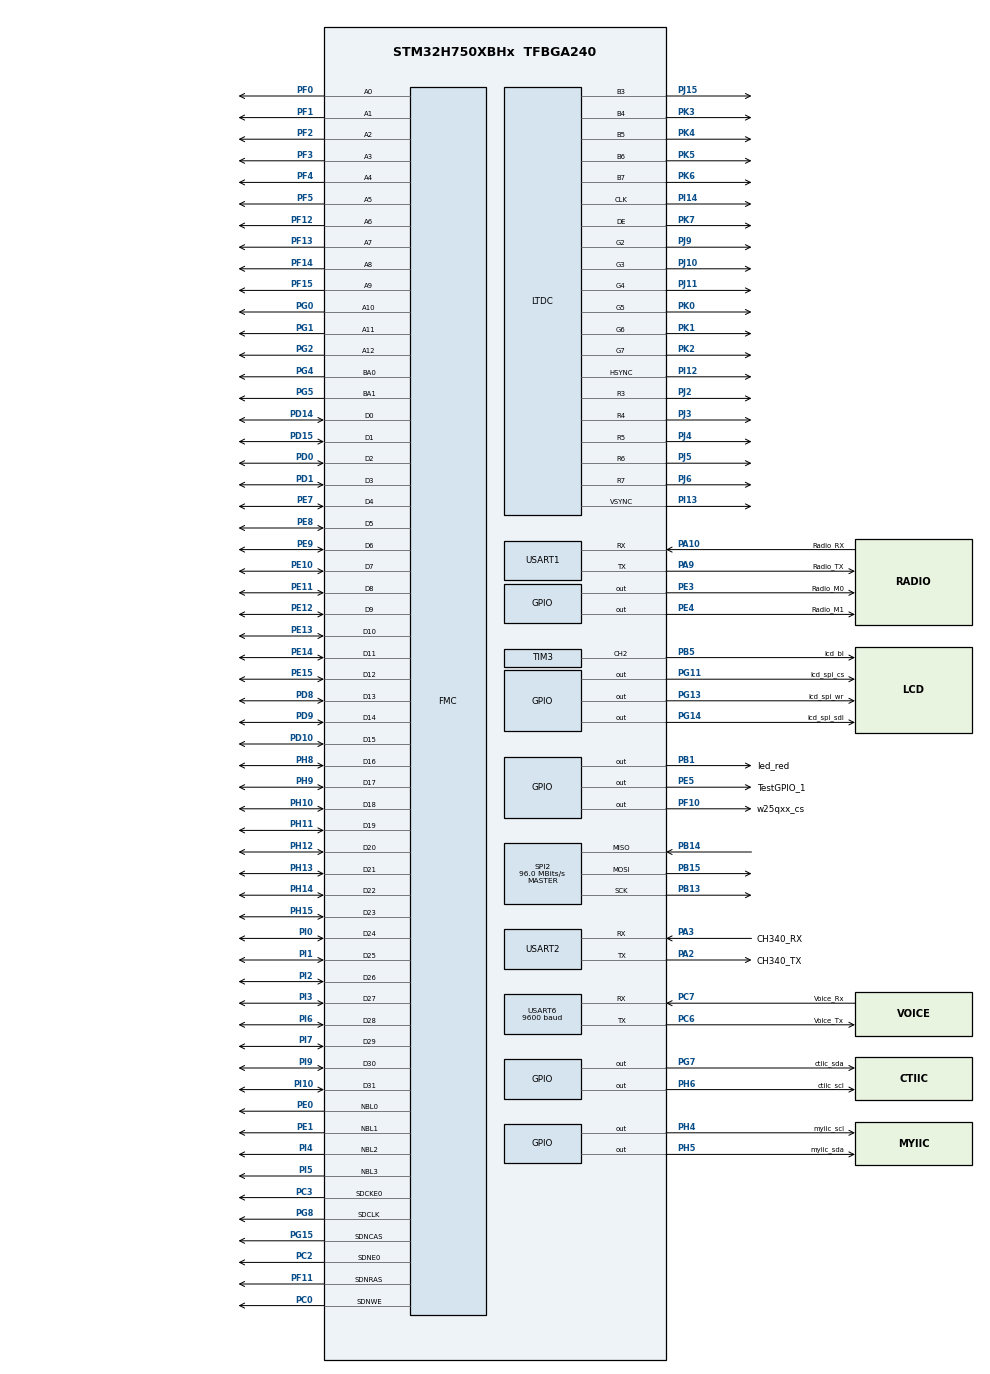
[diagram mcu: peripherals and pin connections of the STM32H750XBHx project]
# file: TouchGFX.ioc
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ADC3.Channel-0\#ChannelRegularConversion=ADC_CHANNEL_TEMPSENSOR
ADC3.ClockPrescalerADC3=ADC_CLOCK_ASYNC_DIV256
ADC3.NbrOfConversionFlag=1
ADC3.OffsetNumber-0\#ChannelRegularConversion=ADC_OFFSET_NONE
ADC3.OffsetSignedSaturation-0\#ChannelRegularConversion=DISABLE
ADC3.Rank-0\#ChannelRegularConversion=1
ADC3.SamplingTime-0\#ChannelRegularConversion=ADC_SAMPLETIME_810CYCLES_5
CORTEX_M7.CPU_DCache=Enabled
CORTEX_M7.CPU_ICache=Enabled
CORTEX_M7.DisableExec_Spec=MPU_INSTRUCTION_ACCESS_ENABLE
CORTEX_M7.Enable_S-Cortex_Memory_Protection_Unit_Region1_Settings_S=__NULL
CORTEX_M7.IsBufferable_Spec=MPU_ACCESS_BUFFERABLE
CORTEX_M7.IsCacheable_Spec=MPU_ACCESS_CACHEABLE
CORTEX_M7.TypeExtField_Spec=MPU_TEX_LEVEL0
CORTEX_M7.default_mode_Activation=1
DMA2D.ColorMode=DMA2D_OUTPUT_RGB565
Dma.Request0=USART1_TX
Dma.USART1_TX.0.Direction=DMA_MEMORY_TO_PERIPH
Dma.USART1_TX.0.EventEnable=DISABLE
Dma.USART1_TX.0.FIFOMode=DMA_FIFOMODE_DISABLE
Dma.USART1_TX.0.Instance=DMA1_Stream0
Dma.USART1_TX.0.MemDataAlignment=DMA_MDATAALIGN_BYTE
Dma.USART1_TX.0.MemInc=DMA_MINC_ENABLE
Dma.USART1_TX.0.Mode=DMA_NORMAL
Dma.USART1_TX.0.PeriphDataAlignment=DMA_PDATAALIGN_BYTE
Dma.USART1_TX.0.PeriphInc=DMA_PINC_DISABLE
Dma.USART1_TX.0.Polarity=HAL_DMAMUX_REQ_GEN_RISING
Dma.USART1_TX.0.Priority=DMA_PRIORITY_LOW
Dma.USART1_TX.0.RequestNumber=1
Dma.USART1_TX.0.SignalID=NONE
Dma.USART1_TX.0.SyncEnable=DISABLE
Dma.USART1_TX.0.SyncPolarity=HAL_DMAMUX_SYNC_NO_EVENT
Dma.USART1_TX.0.SyncRequestNumber=1
Dma.USART1_TX.0.SyncSignalID=NONE
FMC.CASLatency2=FMC_SDRAM_CAS_LATENCY_2
FMC.ColumnBitsNumber2=FMC_SDRAM_COLUMN_BITS_NUM_9
FMC.ExitSelfRefreshDelay2=8
FMC.LoadToActiveDelay2=2
FMC.RCDDelay2=2
FMC.RPDelay1=2
FMC.RPDelay2=2
FMC.ReadBurst1=FMC_SDRAM_RBURST_ENABLE
FMC.ReadBurst2=FMC_SDRAM_RBURST_ENABLE
FMC.RowCycleDelay1=6
FMC.RowCycleDelay2=6
FMC.SDClockPeriod1=FMC_SDRAM_CLOCK_PERIOD_2
FMC.SDClockPeriod2=FMC_SDRAM_CLOCK_PERIOD_2
FMC.SelfRefreshTime2=6
FMC.WriteRecoveryTime2=4
FREERTOS.BinarySemaphores01=RadioUART_BinSem,Dynamic,NULL;RenCPUTempBinSem,Dynamic,NULL;UpRadioDatBinSem,Dynamic,NULL
FREERTOS.INCLUDE_vTaskDelayUntil=1
FREERTOS.Queues01=USB_StateQueue,16,uint8_t,0,Dynamic,NULL,NULL;GUI_ControlTaskQueue,16,uint8_t,0,Dynamic,NULL,NULL;Task_ControlGUIQueue,16,uint8_t,0,Dynamic,NULL,NULL
FREERTOS.Tasks01=touchGFX,2,4096,TouchGFX_Task,As weak,NULL,Dynamic,NULL,NULL;GUI_MesProcess,3,1024,GUI_MesProcess_Task,Default,NULL,Dynamic,NULL,NULL;SendContGUIMess,0,256,SendContGUIMess_Task,Default,NULL,Dynamic,NULL,NULL;IwdgTask,-3,128,StartIwdgTask,Default,NULL,Dynamic,NULL,NULL;PerDataProcess_,1,256,PerDataProcess_Task,Default,NULL,Dynamic,NULL,NULL
FREERTOS.configGENERATE_RUN_TIME_STATS=1
FREERTOS.configTOTAL_HEAP_SIZE=30720
FREERTOS.configUSE_APPLICATION_TASK_TAG=1
FREERTOS.configUSE_COUNTING_SEMAPHORES=1
FREERTOS.configUSE_IDLE_HOOK=1
FREERTOS.configUSE_RECURSIVE_MUTEXES=1
FREERTOS.configUSE_STATS_FORMATTING_FUNCTIONS=1
FREERTOS.configUSE_TICK_HOOK=1
FREERTOS.configUSE_TIMERS=0
FREERTOS.configUSE_TRACE_FACILITY=1
IWDG1.Prescaler=IWDG_PRESCALER_32
IWDG1.Reload=1000
IWDG1.Window=1000
LTDC.ActiveH=800
LTDC.ActiveW=480
LTDC.Alpha_L0=255
LTDC.Alpha_L1=255
LTDC.Blue_L1=255
LTDC.FBStartAdress_L0=0xC0000000
LTDC.Green_L0=0
LTDC.HBP=0x58
LTDC.HFP=0x30
LTDC.HSPolarity=LTDC_HSPOLARITY_AL
LTDC.HSync=0x60
LTDC.ImageHeight_L0=800
LTDC.ImageHeight_L1=800
LTDC.ImageWidth_L0=480
LTDC.Layers=0
LTDC.PCPolarity=LTDC_PCPOLARITY_IPC
LTDC.PixelFormat_L0=LTDC_PIXEL_FORMAT_RGB565
LTDC.VBP=0x03
LTDC.VFP=0x02
LTDC.VSPolarity=LTDC_VSPOLARITY_AL
LTDC.VSync=0x0f
LTDC.WindowX1_L0=480
LTDC.WindowX1_L1=480
LTDC.WindowY1_L0=800
LTDC.WindowY1_L1=800
Mcu.Family=STM32H7
Mcu.Name=STM32H750XBHx
Mcu.Package=TFBGA240
NVIC.DMA1_Stream0_IRQn=true\:5\:0\:false\:false\:true\:true\:false\:true\:true
NVIC.DMA2D_IRQn=true\:9\:0\:true\:false\:true\:true\:true\:true\:true
NVIC.LTDC_IRQn=true\:9\:0\:true\:false\:true\:true\:true\:true\:true
NVIC.PriorityGroup=NVIC_PRIORITYGROUP_4
NVIC.RCC_IRQn=true\:5\:0\:false\:false\:true\:true\:true\:false\:true
NVIC.RTC_Alarm_IRQn=true\:14\:0\:true\:false\:true\:true\:true\:true\:true
NVIC.TIM15_IRQn=true\:6\:0\:true\:false\:true\:true\:true\:true\:true
NVIC.TIM16_IRQn=true\:5\:0\:false\:false\:true\:true\:true\:true\:true
NVIC.TIM6_DAC_IRQn=true\:6\:0\:true\:false\:true\:true\:true\:true\:true
NVIC.TIM7_IRQn=true\:15\:0\:true\:false\:true\:false\:false\:true\:true
NVIC.TIM8_BRK_TIM12_IRQn=true\:7\:0\:true\:false\:true\:true\:true\:true\:true
NVIC.TimeBase=TIM7_IRQn
NVIC.TimeBaseIP=TIM7
NVIC.USART1_IRQn=true\:7\:0\:true\:false\:true\:true\:true\:true\:true
NVIC.USART2_IRQn=true\:6\:0\:true\:false\:true\:true\:true\:true\:true
NVIC.USART6_IRQn=true\:8\:0\:true\:false\:true\:true\:true\:true\:true
PA10.GPIO_Label=Radio_RX
PA10.GPIO_Speed=GPIO_SPEED_FREQ_VERY_HIGH
PA10.Mode=Asynchronous
PA10.Signal=USART1_RX
PA13\ (JTMS/SWDIO).Mode=Serial_Wire
PA13\ (JTMS/SWDIO).Signal=DEBUG_JTMS-SWDIO
PA14\ (JTCK/SWCLK).Mode=Serial_Wire
PA14\ (JTCK/SWCLK).Signal=DEBUG_JTCK-SWCLK
PA2.GPIO_Label=CH340_TX
PA2.GPIO_Speed=GPIO_SPEED_FREQ_VERY_HIGH
PA2.Mode=Asynchronous
PA2.Signal=USART2_TX
PA3.GPIO_Label=CH340_RX
PA3.GPIO_Speed=GPIO_SPEED_FREQ_VERY_HIGH
PA3.Mode=Asynchronous
PA3.Signal=USART2_RX
PA9.GPIO_Label=Radio_TX
PA9.GPIO_Speed=GPIO_SPEED_FREQ_VERY_HIGH
PA9.Mode=Asynchronous
PA9.Signal=USART1_TX
PB1.GPIO_Label=led_red
PB1.GPIO_PuPd=GPIO_PULLUP
PB1.GPIO_Speed=GPIO_SPEED_FREQ_VERY_HIGH
PB1.PinState=GPIO_PIN_SET
PB1.Signal=GPIO_Output
PB13.GPIO_PuPd=GPIO_PULLUP
PB13.GPIO_Speed=GPIO_SPEED_FREQ_VERY_HIGH
PB13.Mode=Full_Duplex_Master
PB13.PinAttribute=Free
PB13.Signal=SPI2_SCK
PB14.GPIO_PuPd=GPIO_PULLUP
PB14.GPIO_Speed=GPIO_SPEED_FREQ_VERY_HIGH
PB14.Mode=Full_Duplex_Master
PB14.PinAttribute=Free
PB14.Signal=SPI2_MISO
PB15.GPIO_PuPd=GPIO_PULLUP
PB15.GPIO_Speed=GPIO_SPEED_FREQ_VERY_HIGH
PB15.Mode=Full_Duplex_Master
PB15.Signal=SPI2_MOSI
PB5.GPIO_Label=lcd_bl
PB5.GPIO_PuPd=GPIO_PULLUP
PB5.GPIO_Speed=GPIO_SPEED_FREQ_VERY_HIGH
PB5.Signal=S_TIM3_CH2
PC0.PinAttribute=Free
PC0.Signal=FMC_SDNWE
PC2.Mode=SdramChipSelect1_2
PC2.PinAttribute=Free
PC2.Signal=FMC_SDNE0
PC3.Mode=SdramChipSelect1_2
PC3.PinAttribute=Free
PC3.Signal=FMC_SDCKE0
PC6.GPIO_Label=Voice_Tx
PC6.GPIO_Speed=GPIO_SPEED_FREQ_VERY_HIGH
PC6.Mode=Asynchronous
PC6.Signal=USART6_TX
PC7.GPIO_Label=Voice_Rx
PC7.GPIO_Speed=GPIO_SPEED_FREQ_VERY_HIGH
PC7.Mode=Asynchronous
PC7.Signal=USART6_RX
PD0.Signal=FMC_D2_DA2
PD1.Signal=FMC_D3_DA3
PD10.Signal=FMC_D15_DA15
PD14.Signal=FMC_D0_DA0
PD15.Signal=FMC_D1_DA1
PD8.PinAttribute=Free
PD8.Signal=FMC_D13_DA13
PD9.Signal=FMC_D14_DA14
PE0.Signal=FMC_NBL0
PE1.PinAttribute=Free
PE1.Signal=FMC_NBL1
PE10.Signal=FMC_D7_DA7
PE11.Signal=FMC_D8_DA8
PE12.Signal=FMC_D9_DA9
PE13.Signal=FMC_D10_DA10
PE14.PinAttribute=Free
PE14.Signal=FMC_D11_DA11
PE15.Signal=FMC_D12_DA12
PE3.GPIO_Label=Radio_M0
PE3.GPIO_Speed=GPIO_SPEED_FREQ_VERY_HIGH
PE3.Signal=GPIO_Output
PE4.GPIO_Label=Radio_M1
PE4.GPIO_PuPd=GPIO_NOPULL
PE4.GPIO_Speed=GPIO_SPEED_FREQ_VERY_HIGH
PE4.Signal=GPIO_Output
PE5.GPIO_Label=TestGPIO_1
PE5.GPIO_PuPd=GPIO_PULLDOWN
PE5.GPIO_Speed=GPIO_SPEED_FREQ_VERY_HIGH
PE5.Signal=GPIO_Output
PE7.PinAttribute=Free
PE7.Signal=FMC_D4_DA4
PE8.Signal=FMC_D5_DA5
PE9.Signal=FMC_D6_DA6
PF0.Signal=FMC_A0
PF1.Signal=FMC_A1
PF10.GPIO_Label=w25qxx_cs
PF10.GPIO_PuPd=GPIO_PULLUP
PF10.GPIO_Speed=GPIO_SPEED_FREQ_VERY_HIGH
PF10.PinState=GPIO_PIN_SET
PF10.Signal=GPIO_Output
PF11.Signal=FMC_SDNRAS
PF12.Signal=FMC_A6
PF13.Signal=FMC_A7
PF14.Signal=FMC_A8
PF15.Signal=FMC_A9
PF2.Signal=FMC_A2
PF3.PinAttribute=Free
PF3.Signal=FMC_A3
PF4.PinAttribute=Free
PF4.Signal=FMC_A4
PF5.PinAttribute=Free
PF5.Signal=FMC_A5
PG0.Signal=FMC_A10
PG1.PinAttribute=Free
PG1.Signal=FMC_A11
PG11.GPIO_Label=lcd_spi_cs
PG11.GPIO_PuPd=GPIO_PULLUP
PG11.GPIO_Speed=GPIO_SPEED_FREQ_VERY_HIGH
PG11.PinAttribute=Free
PG11.PinState=GPIO_PIN_SET
PG11.Signal=GPIO_Output
PG13.GPIO_Label=lcd_spi_wr
PG13.GPIO_PuPd=GPIO_PULLUP
PG13.GPIO_Speed=GPIO_SPEED_FREQ_VERY_HIGH
PG13.PinState=GPIO_PIN_SET
PG13.Signal=GPIO_Output
PG14.GPIO_Label=lcd_spi_sdi
PG14.GPIO_PuPd=GPIO_PULLUP
PG14.GPIO_Speed=GPIO_SPEED_FREQ_VERY_HIGH
PG14.PinState=GPIO_PIN_SET
PG14.Signal=GPIO_Output
PG15.Signal=FMC_SDNCAS
PG2.PinAttribute=Free
PG2.Signal=FMC_A12
PG4.PinAttribute=Free
PG4.Signal=FMC_A14_BA0
PG5.Signal=FMC_A15_BA1
PG7.GPIO_Label=ctiic_sda
PG7.GPIO_PuPd=GPIO_PULLUP
PG7.GPIO_Speed=GPIO_SPEED_FREQ_VERY_HIGH
PG7.PinState=GPIO_PIN_SET
PG7.Signal=GPIO_Output
PG8.Signal=FMC_SDCLK
PH0-OSC_IN\ (PH0).Mode=HSE-External-Oscillator
PH0-OSC_IN\ (PH0).PinAttribute=Free
PH0-OSC_IN\ (PH0).Signal=RCC_OSC_IN
PH1-OSC_OUT\ (PH1).Mode=HSE-External-Oscillator
PH1-OSC_OUT\ (PH1).PinAttribute=Free
PH1-OSC_OUT\ (PH1).Signal=RCC_OSC_OUT
PH10.Signal=FMC_D18
PH11.Signal=FMC_D19
PH12.Signal=FMC_D20
PH13.Signal=FMC_D21
PH14.Signal=FMC_D22
PH15.Signal=FMC_D23
PH4.GPIO_Label=myiic_scl
PH4.GPIO_PuPd=GPIO_PULLUP
PH4.GPIO_Speed=GPIO_SPEED_FREQ_VERY_HIGH
PH4.PinState=GPIO_PIN_SET
PH4.Signal=GPIO_Output
PH5.GPIO_Label=myiic_sda
PH5.GPIO_PuPd=GPIO_PULLUP
PH5.GPIO_Speed=GPIO_SPEED_FREQ_VERY_HIGH
PH5.PinState=GPIO_PIN_SET
PH5.Signal=GPIO_Output
PH6.GPIO_Label=ctiic_scl
PH6.GPIO_PuPd=GPIO_PULLUP
PH6.GPIO_Speed=GPIO_SPEED_FREQ_VERY_HIGH
PH6.PinState=GPIO_PIN_SET
PH6.Signal=GPIO_Output
PH8.Signal=FMC_D16
PH9.Signal=FMC_D17
PI0.PinAttribute=Free
PI0.Signal=FMC_D24
PI1.PinAttribute=Free
PI1.Signal=FMC_D25
PI10.Signal=FMC_D31
PI12.GPIO_PuPd=GPIO_PULLUP
PI12.GPIO_Speed=GPIO_SPEED_FREQ_VERY_HIGH
PI12.Mode=RGB565
PI12.Signal=LTDC_HSYNC
PI13.GPIO_PuPd=GPIO_PULLUP
PI13.GPIO_Speed=GPIO_SPEED_FREQ_VERY_HIGH
PI13.Mode=RGB565
PI13.Signal=LTDC_VSYNC
PI14.GPIO_PuPd=GPIO_PULLUP
PI14.GPIO_Speed=GPIO_SPEED_FREQ_VERY_HIGH
PI14.Mode=RGB565
PI14.PinAttribute=Free
PI14.Signal=LTDC_CLK
PI2.Signal=FMC_D26
PI3.Signal=FMC_D27
PI4.Signal=FMC_NBL2
PI5.Signal=FMC_NBL3
PI6.Signal=FMC_D28
PI7.PinAttribute=Free
PI7.Signal=FMC_D29
PI9.Signal=FMC_D30
PJ10.GPIO_PuPd=GPIO_PULLUP
PJ10.GPIO_Speed=GPIO_SPEED_FREQ_VERY_HIGH
PJ10.Mode=RGB565
PJ10.PinAttribute=Free
PJ10.Signal=LTDC_G3
PJ11.GPIO_PuPd=GPIO_PULLUP
PJ11.GPIO_Speed=GPIO_SPEED_FREQ_VERY_HIGH
PJ11.Mode=RGB565
PJ11.PinAttribute=Free
PJ11.Signal=LTDC_G4
PJ15.GPIO_PuPd=GPIO_PULLUP
PJ15.GPIO_Speed=GPIO_SPEED_FREQ_VERY_HIGH
PJ15.Mode=RGB565
PJ15.Signal=LTDC_B3
PJ2.GPIO_PuPd=GPIO_PULLUP
PJ2.GPIO_Speed=GPIO_SPEED_FREQ_VERY_HIGH
PJ2.Mode=RGB565
PJ2.Signal=LTDC_R3
PJ3.GPIO_PuPd=GPIO_PULLUP
PJ3.GPIO_Speed=GPIO_SPEED_FREQ_VERY_HIGH
PJ3.Mode=RGB565
PJ3.Signal=LTDC_R4
PJ4.GPIO_PuPd=GPIO_PULLUP
PJ4.GPIO_Speed=GPIO_SPEED_FREQ_VERY_HIGH
PJ4.Mode=RGB565
PJ4.PinAttribute=Free
PJ4.Signal=LTDC_R5
PJ5.GPIO_PuPd=GPIO_PULLUP
PJ5.GPIO_Speed=GPIO_SPEED_FREQ_VERY_HIGH
PJ5.Mode=RGB565
PJ5.Signal=LTDC_R6
PJ6.GPIO_PuPd=GPIO_PULLUP
PJ6.GPIO_Speed=GPIO_SPEED_FREQ_VERY_HIGH
PJ6.Mode=RGB565
PJ6.Signal=LTDC_R7
PJ9.GPIO_PuPd=GPIO_PULLUP
PJ9.GPIO_Speed=GPIO_SPEED_FREQ_VERY_HIGH
PJ9.Mode=RGB565
PJ9.Signal=LTDC_G2
PK0.GPIO_PuPd=GPIO_PULLUP
PK0.GPIO_Speed=GPIO_SPEED_FREQ_VERY_HIGH
PK0.Mode=RGB565
PK0.PinAttribute=Free
PK0.Signal=LTDC_G5
PK1.GPIO_PuPd=GPIO_PULLUP
PK1.GPIO_Speed=GPIO_SPEED_FREQ_VERY_HIGH
PK1.Mode=RGB565
PK1.PinAttribute=Free
PK1.Signal=LTDC_G6
PK2.GPIO_PuPd=GPIO_PULLUP
PK2.GPIO_Speed=GPIO_SPEED_FREQ_VERY_HIGH
PK2.Mode=RGB565
PK2.PinAttribute=Free
PK2.Signal=LTDC_G7
PK3.GPIO_PuPd=GPIO_PULLUP
PK3.GPIO_Speed=GPIO_SPEED_FREQ_VERY_HIGH
PK3.Mode=RGB565
PK3.Signal=LTDC_B4
PK4.GPIO_PuPd=GPIO_PULLUP
PK4.GPIO_Speed=GPIO_SPEED_FREQ_VERY_HIGH
PK4.Mode=RGB565
PK4.PinAttribute=Free
PK4.Signal=LTDC_B5
PK5.GPIO_PuPd=GPIO_PULLUP
PK5.GPIO_Speed=GPIO_SPEED_FREQ_VERY_HIGH
PK5.Mode=RGB565
PK5.PinAttribute=Free
PK5.Signal=LTDC_B6
PK6.GPIO_PuPd=GPIO_PULLUP
PK6.GPIO_Speed=GPIO_SPEED_FREQ_VERY_HIGH
PK6.Mode=RGB565
PK6.Signal=LTDC_B7
PK7.GPIO_PuPd=GPIO_PULLUP
PK7.GPIO_Speed=GPIO_SPEED_FREQ_VERY_HIGH
PK7.Mode=RGB565
PK7.Signal=LTDC_DE
ProjectManager.HeapSize=0x10
ProjectManager.StackSize=0x1280
ProjectManager.TargetToolchain=MDK-ARM V5.32
RAMECC.Instance-RAMECC1_Monitor1=RAMECC1_Monitor1
RAMECC.Instance-RAMECC1_Monitor2=RAMECC1_Monitor2
RAMECC.Instance-RAMECC1_Monitor3=RAMECC1_Monitor3
RAMECC.Instance-RAMECC1_Monitor4=RAMECC1_Monitor4
RAMECC.Instance-RAMECC1_Monitor5=RAMECC1_Monitor5
RAMECC.Instance-RAMECC2_Monitor1=RAMECC2_Monitor1
RAMECC.Instance-RAMECC2_Monitor2=RAMECC2_Monitor2
RAMECC.Instance-RAMECC2_Monitor3=RAMECC2_Monitor3
RAMECC.Instance-RAMECC2_Monitor4=RAMECC2_Monitor4
RAMECC.Instance-RAMECC2_Monitor5=RAMECC2_Monitor5
RAMECC.Instance-RAMECC3_Monitor1=RAMECC3_Monitor1
RAMECC.Instance-RAMECC3_Monitor2=RAMECC3_Monitor2
RCC.ADCFreq_Value=72000000
RCC.APB1Freq_Value=120000000
RCC.APB2Freq_Value=120000000
RCC.APB3Freq_Value=120000000
RCC.APB4Freq_Value=120000000
RCC.CortexFreq_Value=480000000
RCC.D1PPRE=RCC_APB3_DIV2
RCC.D2PPRE1=RCC_APB1_DIV2
RCC.D2PPRE2=RCC_APB2_DIV2
RCC.D3PPRE=RCC_APB4_DIV2
RCC.DIVM1=5
RCC.DIVM2=25
RCC.DIVM3=2
RCC.DIVN1=192
RCC.DIVN2=504
RCC.DIVN3=18
RCC.DIVP2=7
RCC.DIVQ1=5
RCC.DIVR3=6
RCC.HCLKFreq_Value=240000000
RCC.HPRE=RCC_HCLK_DIV2
RCC.PLL1_VCI_Range-AdvancedSettings=RCC_PLL1VCIRANGE_0
RCC.PLL2FRACN=0
RCC.PLL3FRACN=0
RCC.PLL3_VCI_Range-AdvancedSettings=RCC_PLL3VCIRANGE_0
RCC.PLLFRACN=0
RCC.PLLSourceVirtual=RCC_PLLSOURCE_HSE
RCC.ProductRev=revV
RCC.RCC_RTC_Clock_Source_FROM_HSE=RCC_RTCCLKSOURCE_HSE_DIV38
RCC.SYSCLKFreq_VALUE=480000000
RCC.SYSCLKSource=RCC_SYSCLKSOURCE_PLLCLK
RCC.USBFreq_Value=192000000
RTC.Alarm-Alarm\ A=RTC_ALARM_A
RTC.AlarmMaskDateWeekDay-Alarm\ A=RTC_ALARMMASK_DATEWEEKDAY
RTC.AlarmMaskHours-Alarm\ A=RTC_ALARMMASK_HOURS
RTC.AlarmMaskMinutes-Alarm\ A=RTC_ALARMMASK_MINUTES
RTC.AlarmMaskSeconds-Alarm\ A=RTC_ALARMMASK_SECONDS
RTC.AlarmSubSecondMask-Alarm\ A=RTC_ALARMSUBSECONDMASK_SS14_9
RTC.AsynchPrediv=0
RTC.Date=30
RTC.Hours=9
RTC.Hours_A-Alarm\ A=9
RTC.Minutes=4
RTC.Minutes_A-Alarm\ A=4
RTC.Month=RTC_MONTH_MARCH
RTC.Seconds_A-Alarm\ A=1
RTC.SynchPrediv=32000-1
RTC.WeekDay=RTC_WEEKDAY_SATURDAY
RTC.Year=24
SH.FMC_A0.0=FMC_A0,13b-sda2
SH.FMC_A1.0=FMC_A1,13b-sda2
SH.FMC_A10.0=FMC_A10,13b-sda2
SH.FMC_A11.0=FMC_A11,13b-sda2
SH.FMC_A12.0=FMC_A12,13b-sda2
SH.FMC_A14_BA0.0=FMC_BA0,FourSdramBanks2
SH.FMC_A15_BA1.0=FMC_BA1,FourSdramBanks2
SH.FMC_A2.0=FMC_A2,13b-sda2
SH.FMC_A3.0=FMC_A3,13b-sda2
SH.FMC_A4.0=FMC_A4,13b-sda2
SH.FMC_A5.0=FMC_A5,13b-sda2
SH.FMC_A6.0=FMC_A6,13b-sda2
SH.FMC_A7.0=FMC_A7,13b-sda2
SH.FMC_A8.0=FMC_A8,13b-sda2
SH.FMC_A9.0=FMC_A9,13b-sda2
SH.FMC_D0_DA0.0=FMC_D0,sd-32b-d2
SH.FMC_D10_DA10.0=FMC_D10,sd-32b-d2
SH.FMC_D11_DA11.0=FMC_D11,sd-32b-d2
SH.FMC_D12_DA12.0=FMC_D12,sd-32b-d2
SH.FMC_D13_DA13.0=FMC_D13,sd-32b-d2
SH.FMC_D14_DA14.0=FMC_D14,sd-32b-d2
SH.FMC_D15_DA15.0=FMC_D15,sd-32b-d2
SH.FMC_D16.0=FMC_D16,sd-32b-d2
SH.FMC_D17.0=FMC_D17,sd-32b-d2
SH.FMC_D18.0=FMC_D18,sd-32b-d2
SH.FMC_D19.0=FMC_D19,sd-32b-d2
SH.FMC_D1_DA1.0=FMC_D1,sd-32b-d2
SH.FMC_D20.0=FMC_D20,sd-32b-d2
SH.FMC_D21.0=FMC_D21,sd-32b-d2
SH.FMC_D22.0=FMC_D22,sd-32b-d2
SH.FMC_D23.0=FMC_D23,sd-32b-d2
SH.FMC_D24.0=FMC_D24,sd-32b-d2
SH.FMC_D25.0=FMC_D25,sd-32b-d2
SH.FMC_D26.0=FMC_D26,sd-32b-d2
SH.FMC_D27.0=FMC_D27,sd-32b-d2
SH.FMC_D28.0=FMC_D28,sd-32b-d2
SH.FMC_D29.0=FMC_D29,sd-32b-d2
SH.FMC_D2_DA2.0=FMC_D2,sd-32b-d2
SH.FMC_D30.0=FMC_D30,sd-32b-d2
SH.FMC_D31.0=FMC_D31,sd-32b-d2
SH.FMC_D3_DA3.0=FMC_D3,sd-32b-d2
SH.FMC_D4_DA4.0=FMC_D4,sd-32b-d2
SH.FMC_D5_DA5.0=FMC_D5,sd-32b-d2
SH.FMC_D6_DA6.0=FMC_D6,sd-32b-d2
SH.FMC_D7_DA7.0=FMC_D7,sd-32b-d2
SH.FMC_D8_DA8.0=FMC_D8,sd-32b-d2
SH.FMC_D9_DA9.0=FMC_D9,sd-32b-d2
SH.FMC_NBL0.0=FMC_NBL0,Sd4ByteEnable2
SH.FMC_NBL1.0=FMC_NBL1,Sd4ByteEnable2
SH.FMC_NBL2.0=FMC_NBL2,Sd4ByteEnable2
SH.FMC_NBL3.0=FMC_NBL3,Sd4ByteEnable2
SH.FMC_SDCLK.0=FMC_SDCLK,13b-sda2
SH.FMC_SDNCAS.0=FMC_SDNCAS,13b-sda2
SH.FMC_SDNRAS.0=FMC_SDNRAS,13b-sda2
SH.FMC_SDNWE.0=FMC_SDNWE,13b-sda2
SH.S_TIM3_CH2.0=TIM3_CH2,PWM Generation2 CH2
SPI2.BaudRatePrescaler=SPI_BAUDRATEPRESCALER_2
SPI2.CalculateBaudRate=96.0 MBits/s
SPI2.Direction=SPI_DIRECTION_2LINES
SPI2.Mode=SPI_MODE_MASTER
SPI2.VirtualType=VM_MASTER
STMicroelectronics.X-CUBE-TOUCHGFX.4.23.2.ApplicationCcGraphicsJjApplication=TouchGFXOoGenerator
STMicroelectronics.X-CUBE-TOUCHGFX.4.23.2.tgfx_address1=0xC0000000
STMicroelectronics.X-CUBE-TOUCHGFX.4.23.2.tgfx_address2=0xC00BB800
STMicroelectronics.X-CUBE-TOUCHGFX.4.23.2.tgfx_buffering_strategy=Double
STMicroelectronics.X-CUBE-TOUCHGFX.4.23.2.tgfx_custom_height=800
STMicroelectronics.X-CUBE-TOUCHGFX.4.23.2.tgfx_display_interface=disp_ltdc
STMicroelectronics.X-CUBE-TOUCHGFX.4.23.2.tgfx_hardware_accelerator=dma_2d
STMicroelectronics.X-CUBE-TOUCHGFX.4.23.2.tgfx_location=By Address
STMicroelectronics.X-CUBE-TOUCHGFX.4.23.2.tgfx_vsync=vsync_ltdc
STMicroelectronics.X-CUBE-TOUCHGFX.4.23.2_IsPackSelfContextualization=true
TIM12.AutoReloadPreload=TIM_AUTORELOAD_PRELOAD_ENABLE
TIM12.Period=10000-1
TIM12.Prescaler=240-1
TIM15.AutoReloadPreload=TIM_AUTORELOAD_PRELOAD_ENABLE
TIM15.Period=1000-1
TIM15.Prescaler=240-1
TIM16.Period=100-1
TIM16.Prescaler=240-1
TIM3.AutoReloadPreload=TIM_AUTORELOAD_PRELOAD_ENABLE
TIM3.Channel-PWM\ Generation2\ CH2=TIM_CHANNEL_2
TIM3.OCPolarity_2=TIM_OCPOLARITY_LOW
TIM3.Period=694-1
TIM3.Prescaler=240-1
TIM3.Pulse-PWM\ Generation2\ CH2=693
TIM6.AutoReloadPreload=TIM_AUTORELOAD_PRELOAD_ENABLE
TIM6.Period=10000-1
TIM6.Prescaler=240-1
USART1.AutoBaudRateEnableParam=UART_ADVFEATURE_AUTOBAUDRATE_DISABLE
USART1.VirtualMode-Asynchronous=VM_ASYNC
USART2.VirtualMode-Asynchronous=VM_ASYNC
USART6.BaudRate=9600
USART6.VirtualMode-Asynchronous=VM_ASYNC
VP_ADC3_TempSens_Input.Mode=IN-TempSens
VP_CRC_VS_CRC.Mode=CRC_Activate
VP_DMA2D_VS_DMA2D.Mode=DMA2D_Activate
VP_FREERTOS_VS_CMSIS_V1.Mode=CMSIS_V1
VP_IWDG1_VS_IWDG.Mode=IWDG_Activate
VP_RAMECC_VS_D1_1.Mode=RAMECC1_Monitor1
VP_RAMECC_VS_D1_2.Mode=RAMECC1_Monitor2
VP_RAMECC_VS_D1_3.Mode=RAMECC1_Monitor3
VP_RAMECC_VS_D1_4.Mode=RAMECC1_Monitor4
VP_RAMECC_VS_D1_5.Mode=RAMECC1_Monitor5
VP_RAMECC_VS_D2_1.Mode=RAMECC2_Monitor1
VP_RAMECC_VS_D2_2.Mode=RAMECC2_Monitor2
VP_RAMECC_VS_D2_3.Mode=RAMECC2_Monitor3
VP_RAMECC_VS_D2_4.Mode=RAMECC2_Monitor4
VP_RAMECC_VS_D2_5.Mode=RAMECC2_Monitor5
VP_RAMECC_VS_D3_1.Mode=RAMECC3_Monitor1
VP_RAMECC_VS_D3_2.Mode=RAMECC3_Monitor2
VP_RNG_VS_RNG.Mode=RNG_Activate
VP_RTC_VS_RTC_Activate.Mode=RTC_Enabled
VP_RTC_VS_RTC_Alarm_A_Intern.Mode=Alarm A
VP_RTC_VS_RTC_Calendar.Mode=RTC_Calendar
VP_STMicroelectronics.X-CUBE-TOUCHGFX_VS_GraphicsJjApplication_4.23.2.Mode=GraphicsJjApplication
VP_SYS_VS_tim7.Mode=TIM7
VP_TIM12_VS_ClockSourceINT.Mode=Internal
VP_TIM15_VS_ClockSourceINT.Mode=Internal
VP_TIM16_VS_ClockSourceINT.Mode=Enable_Timer
VP_TIM3_VS_ClockSourceINT.Mode=Internal
VP_TIM6_VS_ClockSourceINT.Mode=Enable_Timer
board=custom

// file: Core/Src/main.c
/* USER CODE BEGIN Header */
/**
  ******************************************************************************
  * @file           : main.c
  * @brief          : Main program body
  ******************************************************************************
  * @attention
  *
  * Copyright (c) 2023 STMicroelectronics.
  * All rights reserved.
  *
  * This software is licensed under terms that can be found in the LICENSE file
  * in the root directory of this software component.
  * If no LICENSE file comes with this software, it is provided AS-IS.
  *
  ******************************************************************************
  */
/* USER CODE END Header */
#include "main.h"
#include "cmsis_os.h"
#include "adc.h"
#include "crc.h"
#include "dma.h"
#include "dma2d.h"
#include "iwdg.h"
#include "ltdc.h"
#include "ramecc.h"
#include "rng.h"
#include "rtc.h"
#include "spi.h"
#include "tim.h"
#include "usart.h"
#include "gpio.h"
#include "fmc.h"
#include "app_touchgfx.h"

/* USER CODE BEGIN Includes */
#include "sys.h"
#include "delay.h"
#include "Radio.h"
#include "w25qxx.h"
#include "Voice.h"
#include "24cxx.h"
#include "Backlight.h"
#include "Voice.h"
#include "malloc.h"

#include "usbd_core.h"
#include "usbd_desc.h"
#include "usbd_msc.h"
#include "usbd_storage.h"

#include "tim_it.h"

#include "ff.h"
#include "myFatFs.h"

#include <stdio.h>
#include <string.h>
#include <stdlib.h>

#include "usmart_cmd_input.h"
#include "usmart.h"

#include "arm_math.h"
/* USER CODE END Includes */

/* USER CODE BEGIN PD */
MAIN_FREERTOS_GlobalVariableStructure MAIN_FREERTOS_GlobalVariableStruct={0};
/* USER CODE END PD */

/* USER CODE BEGIN PV */
uint32_t g_osRuntimeCounter = 0;

char g_tasks_buf[512]; //用于存放显示数据
/* USER CODE END PV */

void SystemClock_Config(void);
static void MPU_Config(void);
void MX_FREERTOS_Init(void);

/* USER CODE BEGIN 0 */
////浣胯兘STM32H7鐨凩1-Cache,鍚屾椂寮?鍚疍 cache鐨勫己鍒�??忓啓
//void Cache_Enable(void)
//{
//    SCB_EnableICache();	//浣胯兘I-Cache,鍑芥暟鍦╟ore_cm7.h閲岄潰�?�氫�?
//    SCB_EnableDCache();	//浣胯兘D-Cache,鍑芥暟鍦╟ore_cm7.h閲岄潰�?�氫�?
//	SCB->CACR|=1<<2;	//寮哄埗D-Cache閫忓�?,濡備笉寮?鍚?忓啓,瀹為檯浣跨敤涓彲鑳介亣鍒板悇绉嶉棶�??
//}

//瑁佸�?瀛楃涓?
static char* substring(char* dst, char* src, int start, int len)
{
    int length = 100;//�??澶ч暱�??
    if (start >= length || start < 0)
        return NULL;
    if (len > length)
        len = length - start;
    src += start;
    while (len--)
    {
        *(dst++) = *(src++);
    }
    *(dst++) = '\0';
    return dst;
}
/* USER CODE END 0 */

int main(void)
{

  /* USER CODE BEGIN 1 */

//      /* Enable I-Cache---------------------------------------------------------*/
//    SCB_EnableICache();

//    /* Enable D-Cache---------------------------------------------------------*/
//    SCB_EnableDCache();
  /* USER CODE END 1 */

  /* MPU Configuration--------------------------------------------------------*/
  MPU_Config();

  /* Enable the CPU Cache */

  /* Enable I-Cache---------------------------------------------------------*/
  SCB_EnableICache();

  /* Enable D-Cache---------------------------------------------------------*/
  SCB_EnableDCache();

  /* MCU Configuration--------------------------------------------------------*/

  /* Reset of all peripherals, Initializes the Flash interface and the Systick. */
  HAL_Init();

  /* Configure the system clock */
  SystemClock_Config();

  /* USER CODE BEGIN SysInit */
    QSPI_Enable_Memmapmode();
    Cache_Enable();
    delay_init(480);
  /* USER CODE END SysInit */

  /* Initialize all configured peripherals */
  MX_GPIO_Init();
  MX_DMA_Init();
  MX_DMA2D_Init();
  MX_USART1_UART_Init();
  MX_TIM3_Init();
  MX_USART6_UART_Init();
  MX_SPI2_Init();
  MX_ADC3_Init();
  MX_TIM6_Init();
  MX_LTDC_Init();
  MX_FMC_Init();
  MX_USART2_UART_Init();
  MX_TIM15_Init();
  MX_TIM12_Init();
  MX_TIM16_Init();
  MX_IWDG1_Init();
  MX_RTC_Init();
  MX_RNG_Init();
  MX_CRC_Init();
  MX_RAMECC_Init();
  MX_TouchGFX_Init();
  /* Call PreOsInit function */
  MX_TouchGFX_PreOSInit();
  /* USER CODE BEGIN 2 */
  /*鍦∕X_FMC_Init();鍚庢坊鍔�?
  Lcd_Initialize();   \
  鍒濆鍖?*/

    delay_ms(1000);//绛夊緟鏌愪簺鍣ㄤ欢涓婄數

//    delay_ms(5000);

    //鍚姩鏃犵嚎鐢垫帴鏀?
    HAL_UART_Receive_IT(&huart1, &RadioRTxStru.Receive, 1);
    HAL_UART_Transmit_DMA(&huart1, (uint8_t*)"Read", 1);//鍏堝彂閫佺�??涓暟鎹紝涓嬩竴甯ц兘澶熷彂閫佹垚鍔?

    HAL_UART_Receive_IT(&huart6, &VoiceRTxStru.Receive, 1);

    //�?启串口接收中�?
    HAL_UART_Receive_IT(&huart2, &UART_USMART_Struct.Receive, 1);
    //__HAL_UART_ENABLE_IT(&huart2, UART_IT_IDLE);

    //�?启定时器中断，用于判断串口空闲中�?
    HAL_TIM_Base_Start_IT(&htim15);

    //�?启定时器中断，用做定时任务处理（osDelay不准确）
    HAL_TIM_Base_Start_IT(&htim12);

    HAL_TIM_Base_Start_IT(&htim16); //�?启freeRtos系统计数定时器，要求中断时间至少�?100us

    usmart_dev.init(0);	//执行usmart初始�?

    W25QXX_Init();					//W25QXX鍒濆鍖?
    while (W25QXX_ReadID() != W25Q256);
    AT24CXX_Init();					//IIC鍒濆鍖?
    while (AT24CXX_Check());//�??娴嬩笉鍒?24c02

    my_mem_init(SRAMIN);			//鍒濆鍖栧唴閮ㄥ唴�?�樻�?(AXI)
    my_mem_init(SRAMEX);

      //璇煶鍒濆�??
    SetVoiceVolume(GetVoiceVolume());
    delay_ms(50);
    SetVoiceVolume(GetVoiceVolume());
    delay_ms(50);
    SetVoiceVolume(GetVoiceVolume());
    delay_ms(50);
    VoicePlayback(1);
    delay_ms(50);
    VoicePlayback(1);
    delay_ms(50);
    VoicePlayback(1);
    delay_ms(50);

    //SaveBacklight(560);
    SetBacklight(AT24CXX_ReadOneByte(0) * 10);//�??鍚儗鍏?
    //鏍�?�噯ADC
    HAL_ADCEx_Calibration_Start(&hadc3, ADC_CALIB_OFFSET, ADC_SINGLE_ENDED);
    //  //�??鍚畾鏃跺櫒
    //  HAL_TIM_Base_Start_IT(&htim6);

    uint8_t FatFs_temp;

    f_open(&FIL_GlobalVariableStruct.file, (char*)"1:POWER ON.ini", FA_READ);

    char read_buff[50];
    char dst[10];

    f_lseek(&FIL_GlobalVariableStruct.file, f_size(&FIL_GlobalVariableStruct.file) - 22);

    f_read(&FIL_GlobalVariableStruct.file, read_buff, sizeof read_buff, NULL);

    printf("%s", read_buff);

    for (uint8_t i = 0; i < 34 - 2; i++)
    {
        if (read_buff[i] == ' ' && read_buff[i + 1] == ':' && read_buff[i + 2] == ' ')
        {
            substring(dst, read_buff, i + 4, 3);
            FatFs_temp = atoi((const char*)dst);
        }
    }
    printf("�?机次�?:%d", FatFs_temp);
    /* 鍏抽棴鏂囦欢 */
    f_close(&FIL_GlobalVariableStruct.file);

    f_open(&FIL_GlobalVariableStruct.file, (char*)"1:POWER ON.ini", FA_WRITE);
    /* 杩藉姞鍒版枃浠剁殑缁撳熬 */
    f_lseek(&FIL_GlobalVariableStruct.file, f_size(&FIL_GlobalVariableStruct.file));
    f_printf(&FIL_GlobalVariableStruct.file, "系统�?机次�? : <%03d>\r\n", ++FatFs_temp);
    /* 鍏抽棴鏂囦欢 */
    f_close(&FIL_GlobalVariableStruct.file);
  /* USER CODE END 2 */

  /* Call init function for freertos objects (in cmsis_os2.c) */
  MX_FREERTOS_Init();

  /* Start scheduler */
  osKernelStart();

  /* We should never get here as control is now taken by the scheduler */

  /* Infinite loop */
    while (1)
    {

    }
}

void SystemClock_Config(void)
{
  RCC_OscInitTypeDef RCC_OscInitStruct = {0};
  RCC_ClkInitTypeDef RCC_ClkInitStruct = {0};

  /** Supply configuration update enable
  */
  HAL_PWREx_ConfigSupply(PWR_LDO_SUPPLY);

  /** Configure the main internal regulator output voltage
  */
  __HAL_PWR_VOLTAGESCALING_CONFIG(PWR_REGULATOR_VOLTAGE_SCALE1);

  while(!__HAL_PWR_GET_FLAG(PWR_FLAG_VOSRDY)) {}

  __HAL_RCC_SYSCFG_CLK_ENABLE();
  __HAL_PWR_VOLTAGESCALING_CONFIG(PWR_REGULATOR_VOLTAGE_SCALE0);

  while(!__HAL_PWR_GET_FLAG(PWR_FLAG_VOSRDY)) {}

  /** Initializes the RCC Oscillators according to the specified parameters
  * in the RCC_OscInitTypeDef structure.
  */
  RCC_OscInitStruct.OscillatorType = RCC_OSCILLATORTYPE_HSI48|RCC_OSCILLATORTYPE_LSI
                              |RCC_OSCILLATORTYPE_HSE;
  RCC_OscInitStruct.HSEState = RCC_HSE_ON;
  RCC_OscInitStruct.LSIState = RCC_LSI_ON;
  RCC_OscInitStruct.HSI48State = RCC_HSI48_ON;
  RCC_OscInitStruct.PLL.PLLState = RCC_PLL_ON;
  RCC_OscInitStruct.PLL.PLLSource = RCC_PLLSOURCE_HSE;
  RCC_OscInitStruct.PLL.PLLM = 5;
  RCC_OscInitStruct.PLL.PLLN = 192;
  RCC_OscInitStruct.PLL.PLLP = 2;
  RCC_OscInitStruct.PLL.PLLQ = 5;
  RCC_OscInitStruct.PLL.PLLR = 2;
  RCC_OscInitStruct.PLL.PLLRGE = RCC_PLL1VCIRANGE_2;
  RCC_OscInitStruct.PLL.PLLVCOSEL = RCC_PLL1VCOWIDE;
  RCC_OscInitStruct.PLL.PLLFRACN = 0;
  if (HAL_RCC_OscConfig(&RCC_OscInitStruct) != HAL_OK)
  {
    Error_Handler();
  }

  /** Initializes the CPU, AHB and APB buses clocks
  */
  RCC_ClkInitStruct.ClockType = RCC_CLOCKTYPE_HCLK|RCC_CLOCKTYPE_SYSCLK
                              |RCC_CLOCKTYPE_PCLK1|RCC_CLOCKTYPE_PCLK2
                              |RCC_CLOCKTYPE_D3PCLK1|RCC_CLOCKTYPE_D1PCLK1;
  RCC_ClkInitStruct.SYSCLKSource = RCC_SYSCLKSOURCE_PLLCLK;
  RCC_ClkInitStruct.SYSCLKDivider = RCC_SYSCLK_DIV1;
  RCC_ClkInitStruct.AHBCLKDivider = RCC_HCLK_DIV2;
  RCC_ClkInitStruct.APB3CLKDivider = RCC_APB3_DIV2;
  RCC_ClkInitStruct.APB1CLKDivider = RCC_APB1_DIV2;
  RCC_ClkInitStruct.APB2CLKDivider = RCC_APB2_DIV2;
  RCC_ClkInitStruct.APB4CLKDivider = RCC_APB4_DIV2;

  if (HAL_RCC_ClockConfig(&RCC_ClkInitStruct, FLASH_LATENCY_4) != HAL_OK)
  {
    Error_Handler();
  }
}

 /* MPU Configuration */

void MPU_Config(void)
{
  MPU_Region_InitTypeDef MPU_InitStruct = {0};

  /* Disables the MPU */
  HAL_MPU_Disable();

  /** Initializes and configures the Region and the memory to be protected
  */
  MPU_InitStruct.Enable = MPU_REGION_ENABLE;
  MPU_InitStruct.Number = MPU_REGION_NUMBER0;
  MPU_InitStruct.BaseAddress = 0x0;
  MPU_InitStruct.Size = MPU_REGION_SIZE_4GB;
  MPU_InitStruct.SubRegionDisable = 0x87;
  MPU_InitStruct.TypeExtField = MPU_TEX_LEVEL0;
  MPU_InitStruct.AccessPermission = MPU_REGION_NO_ACCESS;
  MPU_InitStruct.DisableExec = MPU_INSTRUCTION_ACCESS_ENABLE;
  MPU_InitStruct.IsShareable = MPU_ACCESS_SHAREABLE;
  MPU_InitStruct.IsCacheable = MPU_ACCESS_CACHEABLE;
  MPU_InitStruct.IsBufferable = MPU_ACCESS_BUFFERABLE;

  HAL_MPU_ConfigRegion(&MPU_InitStruct);
  /* Enables the MPU */
  HAL_MPU_Enable(MPU_PRIVILEGED_DEFAULT);

}

void HAL_TIM_PeriodElapsedCallback(TIM_HandleTypeDef *htim)
{
  if (htim->Instance == TIM7) {
    HAL_IncTick();
  }
  /* USER CODE BEGIN Callback 1 */
    if (htim->Instance == TIM6)
        HAL_TIM6_PeriodElapsedCallback(htim);
    if (htim->Instance == TIM15)
        HAL_TIM15_PeriodElapsedCallback(htim);
    if (htim->Instance == TIM12)
        HAL_TIM12_PeriodElapsedCallback(htim);
    if (htim->Instance == TIM16)
        g_osRuntimeCounter++;
  /* USER CODE END Callback 1 */
}

void Error_Handler(void)
{
    __disable_irq();
    while (1)
    {
    }
}

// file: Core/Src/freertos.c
/* USER CODE BEGIN Header */
/**
  ******************************************************************************
  * File Name          : freertos.c
  * Description        : Code for freertos applications
  ******************************************************************************
  * @attention
  *
  * Copyright (c) 2023 STMicroelectronics.
  * All rights reserved.
  *
  * This software is licensed under terms that can be found in the LICENSE file
  * in the root directory of this software component.
  * If no LICENSE file comes with this software, it is provided AS-IS.
  *
  ******************************************************************************
  */
/* USER CODE END Header */

#include "FreeRTOS.h"
#include "task.h"
#include "main.h"
#include "cmsis_os.h"

/* USER CODE BEGIN Includes */
#include "usart.h"
#include "Radio.h"

#include "adc.h"
#include "my_adc.h"
#include "iwdg.h"
#include "rtc.h"

#include "InfoNES.h"
#include "ltdc.h"

#include "ft5206.h"
TouchTypedef mtouch;

#include "InfoNES.h"
#include "InfoNES_System.h"
#include "InfoNES_Mapper.h"
#include "InfoNES_pAPU.h"
#include "K6502.h"
#include "ltdc.h"
/* USER CODE END Includes */

/* USER CODE BEGIN PTD */
#include "usbd_core.h"
#include "usbd_desc.h"
#include "usbd_msc.h"
#include "usbd_storage.h"

#include "usmart.h"

#include "InfoNES.h"
#include "InfoNES.h"
#include "InfoNES_System.h"
#include "InfoNES_Mapper.h"
#include "InfoNES_pAPU.h"
#include "K6502.h"
/* USER CODE END PTD */

/* USER CODE BEGIN PD */

extern uint32_t g_osRuntimeCounter;
extern char g_tasks_buf[512]; //用于存放显示数据
/* USER CODE END PD */

/* USER CODE BEGIN Variables */
EventGroupHandle_t IWDG_Event;//创建事件组句柄
/* USER CODE END Variables */
osThreadId touchGFXHandle;
osThreadId GUI_MesProcessHandle;
osThreadId SendContGUIMessHandle;
osThreadId IwdgTaskHandle;
osThreadId PerDataProcess_Handle;
osMessageQId USB_StateQueueHandle;
osMessageQId GUI_ControlTaskQueueHandle;
osMessageQId Task_ControlGUIQueueHandle;
osSemaphoreId RadioUART_BinSemHandle;
osSemaphoreId RenCPUTempBinSemHandle;
osSemaphoreId UpRadioDatBinSemHandle;

void TouchGFX_Task(void const * argument);
void GUI_MesProcess_Task(void const * argument);
void SendContGUIMess_Task(void const * argument);
void StartIwdgTask(void const * argument);
void PerDataProcess_Task(void const * argument);

void MX_FREERTOS_Init(void); /* (MISRA C 2004 rule 8.1) */

/* GetIdleTaskMemory prototype (linked to static allocation support) */
void vApplicationGetIdleTaskMemory( StaticTask_t **ppxIdleTaskTCBBuffer, StackType_t **ppxIdleTaskStackBuffer, uint32_t *pulIdleTaskStackSize );

/* Hook prototypes */
void configureTimerForRunTimeStats(void);
unsigned long getRunTimeCounterValue(void);
void vApplicationIdleHook(void);
void vApplicationTickHook(void);

/* USER CODE BEGIN 1 */
void debugShowOSTasksLists(void);

void debugShowOSTasksRunTimeStats(void);

void debugShowOSTasksLists(void)
{
#if ( ( configUSE_TRACE_FACILITY == 1 ) && ( configUSE_STATS_FORMATTING_FUNCTIONS > 0 ) )

    memset(g_tasks_buf, 0, 512);

    strcat((char*)g_tasks_buf, "\r\n任务名称 运行状态 优先级 剩余堆栈 任务序号\r\n");

    strcat((char*)g_tasks_buf, "---------------------------------------------\r\n");

    /* The list of tasks and their status */

    //osThreadList ((char *)(g_tasks_buf + strlen(g_tasks_buf)));

    vTaskList((char*)(g_tasks_buf + strlen(g_tasks_buf)));

    strcat((char*)g_tasks_buf, "---------------------------------------------\r\n");

    //strcat((char *)g_tasks_buf, "B : Blocked, R : Ready, D : Deleted, S : Suspended\r\n");

    strcat((char*)g_tasks_buf, "B : 阻塞, R : 就绪, D : 删除, S : 暂停\r\n");

    //UART1SendLen((uint8_t*)g_tasks_buf, strlen(g_tasks_buf));
    printf("%s\r\n", g_tasks_buf);
#endif

}

void debugShowOSTasksRunTimeStats(void)
{
#if ( ( configGENERATE_RUN_TIME_STATS == 1 ) && ( configUSE_STATS_FORMATTING_FUNCTIONS > 0 ) )

    memset(g_tasks_buf, 0, 512);

    strcat((char*)g_tasks_buf, "\r\n任务名称\t运行计数\t使用率\r\n");

    strcat((char*)g_tasks_buf, "---------------------------------------------\r\n");

    /* displays the amount of time each task has spent in the Running state

    * in both absolute and percentage terms. */

    vTaskGetRunTimeStats((char*)(g_tasks_buf + strlen(g_tasks_buf)));

    strcat((char*)g_tasks_buf, "---------------------------------------------\r\n");

    //UART1SendLen((uint8_t*)g_tasks_buf, strlen(g_tasks_buf));
    printf("%s\r\n", g_tasks_buf);
#endif

}
/* Functions needed when configGENERATE_RUN_TIME_STATS is on */
__weak void configureTimerForRunTimeStats(void)
{
    g_osRuntimeCounter = 0;
}

__weak unsigned long getRunTimeCounterValue(void)
{
    return g_osRuntimeCounter;
}
/* USER CODE END 1 */

/* USER CODE BEGIN 2 */
#define CPU_USAGE_CALC_TICK 100
#define CPU_USAGE_LOOP      100

__weak void vApplicationIdleHook(void)
{
    /* vApplicationIdleHook() will only be called if configUSE_IDLE_HOOK is set
    to 1 in FreeRTOSConfig.h. It will be called on each iteration of the idle
    task. It is essential that code added to this hook function never attempts
    to block in any way (for example, call xQueueReceive() with a block time
    specified, or call vTaskDelay()). If the application makes use of the
    vTaskDelete() API function (as this demo application does) then it is also
    important that vApplicationIdleHook() is permitted to return to its calling
    function, because it is the responsibility of the idle task to clean up
    memory allocated by the kernel to any task that has since been deleted. */

    unsigned int tick;
    unsigned int count;
    volatile unsigned int loop;

    if (MAIN_FREERTOS_GlobalVariableStruct.total_count == 0)
    {
        vTaskSuspendAll();
        tick = HAL_GetTick();

        while (HAL_GetTick() - tick < CPU_USAGE_CALC_TICK)
        {
            MAIN_FREERTOS_GlobalVariableStruct.total_count++;
            loop = 0;
            while (loop < CPU_USAGE_LOOP)loop++;
        }
        xTaskResumeAll();
    }

    count = 0;
    tick = HAL_GetTick();

    while (HAL_GetTick() - tick < CPU_USAGE_CALC_TICK)
    {
        count++;
        loop = 0;
        while (loop < CPU_USAGE_LOOP)loop++;
    }

    if (count < MAIN_FREERTOS_GlobalVariableStruct.total_count)
    {
        count = MAIN_FREERTOS_GlobalVariableStruct.total_count - count;
        MAIN_FREERTOS_GlobalVariableStruct.cpu_usage = (count * 100) / MAIN_FREERTOS_GlobalVariableStruct.total_count;
    }
    else
    {
        MAIN_FREERTOS_GlobalVariableStruct.total_count = count;
        MAIN_FREERTOS_GlobalVariableStruct.cpu_usage = 0;
    }
}
/* USER CODE END 2 */

/* USER CODE BEGIN 3 */
__weak void vApplicationTickHook(void)
{
    /* This function will be called by each tick interrupt if
    configUSE_TICK_HOOK is set to 1 in FreeRTOSConfig.h. User code can be
    added here, but the tick hook is called from an interrupt context, so
    code must not attempt to block, and only the interrupt safe FreeRTOS API
    functions can be used (those that end in FromISR()). */
}
/* USER CODE END 3 */

/* USER CODE BEGIN GET_IDLE_TASK_MEMORY */
static StaticTask_t xIdleTaskTCBBuffer;
static StackType_t xIdleStack[configMINIMAL_STACK_SIZE];

void vApplicationGetIdleTaskMemory(StaticTask_t** ppxIdleTaskTCBBuffer, StackType_t** ppxIdleTaskStackBuffer, uint32_t* pulIdleTaskStackSize)
{
    *ppxIdleTaskTCBBuffer = &xIdleTaskTCBBuffer;
    *ppxIdleTaskStackBuffer = &xIdleStack[0];
    *pulIdleTaskStackSize = configMINIMAL_STACK_SIZE;
    /* place for user code */
}
/* USER CODE END GET_IDLE_TASK_MEMORY */

void MX_FREERTOS_Init(void) {
  /* USER CODE BEGIN Init */
    IWDG_Event = xEventGroupCreate(); //创建事件组
  /* USER CODE END Init */

  /* Create the semaphores(s) */
  /* definition and creation of RadioUART_BinSem */
  osSemaphoreDef(RadioUART_BinSem);
  RadioUART_BinSemHandle = osSemaphoreCreate(osSemaphore(RadioUART_BinSem), 1);

  /* definition and creation of RenCPUTempBinSem */
  osSemaphoreDef(RenCPUTempBinSem);
  RenCPUTempBinSemHandle = osSemaphoreCreate(osSemaphore(RenCPUTempBinSem), 1);

  /* definition and creation of UpRadioDatBinSem */
  osSemaphoreDef(UpRadioDatBinSem);
  UpRadioDatBinSemHandle = osSemaphoreCreate(osSemaphore(UpRadioDatBinSem), 1);

  /* Create the queue(s) */
  /* definition and creation of USB_StateQueue */
  osMessageQDef(USB_StateQueue, 16, uint8_t);
  USB_StateQueueHandle = osMessageCreate(osMessageQ(USB_StateQueue), NULL);

  /* definition and creation of GUI_ControlTaskQueue */
  osMessageQDef(GUI_ControlTaskQueue, 16, uint8_t);
  GUI_ControlTaskQueueHandle = osMessageCreate(osMessageQ(GUI_ControlTaskQueue), NULL);

  /* definition and creation of Task_ControlGUIQueue */
  osMessageQDef(Task_ControlGUIQueue, 16, uint8_t);
  Task_ControlGUIQueueHandle = osMessageCreate(osMessageQ(Task_ControlGUIQueue), NULL);

  /* Create the thread(s) */
  /* definition and creation of touchGFX */
  osThreadDef(touchGFX, TouchGFX_Task, osPriorityHigh, 0, 4096);
  touchGFXHandle = osThreadCreate(osThread(touchGFX), NULL);

  /* definition and creation of GUI_MesProcess */
  osThreadDef(GUI_MesProcess, GUI_MesProcess_Task, osPriorityRealtime, 0, 1024);
  GUI_MesProcessHandle = osThreadCreate(osThread(GUI_MesProcess), NULL);

  /* definition and creation of SendContGUIMess */
  osThreadDef(SendContGUIMess, SendContGUIMess_Task, osPriorityNormal, 0, 256);
  SendContGUIMessHandle = osThreadCreate(osThread(SendContGUIMess), NULL);

  /* definition and creation of IwdgTask */
  osThreadDef(IwdgTask, StartIwdgTask, osPriorityIdle, 0, 128);
  IwdgTaskHandle = osThreadCreate(osThread(IwdgTask), NULL);

  /* definition and creation of PerDataProcess_ */
  osThreadDef(PerDataProcess_, PerDataProcess_Task, osPriorityAboveNormal, 0, 256);
  PerDataProcess_Handle = osThreadCreate(osThread(PerDataProcess_), NULL);

}

__weak void TouchGFX_Task(void const * argument)
{
    for (;;)
    {
        osDelay(1);
    }
}

/* USER CODE BEGIN Header_GUI_MesProcess_Task */
/**
* @brief Function implementing the GUI_MesProcess thread.
* @param argument: Not used
* @retval None
*/
u8 key_data=0;

#include "rtc.h"
RTC_TimeTypeDef Time;

u8 falg_scankey=0;

uint8_t button_key;
/* USER CODE END Header_GUI_MesProcess_Task */
void GUI_MesProcess_Task(void const * argument)
{
  /* USER CODE BEGIN GUI_MesProcess_Task */
    osEvent event;
    /* Infinite loop */
    for (;;)
    {
        //标记事件组
        xEventGroupSetBits(IWDG_Event, IWDG_Event_2);
        osDelay(10);

        //GUI消息队列
        event = osMessageGet(GUI_ControlTaskQueueHandle, 0);
        if (event.status == osEventMessage)
        {
            if (event.value.v == GUIConTaskQueFanON)
            {
                printf("打开风扇\r\n");
                HAL_GPIO_WritePin(GPIOE, GPIO_PIN_5, GPIO_PIN_SET);
            }
            else if (event.value.v == GUIConTaskQueFanOFF)
            {
                printf("关闭风扇\r\n");
                HAL_GPIO_WritePin(GPIOE, GPIO_PIN_5, GPIO_PIN_RESET);
            }
            //NES
            else if (event.value.v == GUIConTaskQueNESStart)
            {
                MX_LTDC_Init();

                #include "voice.h"
                VoicePlayback(2);
                osDelay(50);
                VoicePlayback(2);
                osDelay(50);
                VoicePlayback(2);
                osDelay(50);

                //初始化触摸屏
                FT5206_Init();
                mtouch.dir = 1;
                mtouch.pix_h = 800;
                mtouch.pix_w = 480;

                if(InfoNES_Load(NULL)==0)
                {
                    // Initialize InfoNES
                    InfoNES_Init();
                }
                while(1)
                {
                    if ( InfoNES_Menu() == -1 )
                        break;  // Quit

                    int nStep;

                    // Set a flag if a scanning line is a hit in the sprite #0
                    if ( SpriteJustHit == PPU_Scanline &&
                      PPU_ScanTable[ PPU_Scanline ] == SCAN_ON_SCREEN )
                    {
                      // # of Steps to execute before sprite #0 hit
                      nStep = JustHitStep[SPRRAM[ SPR_X ]];

                      // Execute instructions
                      K6502_Step( nStep );

                      // Set a sprite hit flag
                      if ( ( PPU_R1 & R1_SHOW_SP ) && ( PPU_R1 & R1_SHOW_SCR ) )
                        PPU_R2 |= R2_HIT_SP;

                      // NMI is required if there is necessity
                      if ( ( PPU_R0 & R0_NMI_SP ) && ( PPU_R1 & R1_SHOW_SP ) )
                        NMI_REQ;

                      // Execute instructions
                      K6502_Step( STEP_PER_SCANLINE - nStep );
                    }
                    else
                    {
                      // Execute instructions
                      K6502_Step( STEP_PER_SCANLINE );
                    }

                    // Frame IRQ in H-Sync
                    FrameStep += STEP_PER_SCANLINE;
                    if ( FrameStep > STEP_PER_FRAME && FrameIRQ_Enable )
                    {
                      FrameStep %= STEP_PER_FRAME;
                      IRQ_REQ;
                #ifndef APU_NONE
                      APU_Reg[ 0x4015 ] |= 0x40;
                #endif /* APU_NONE */
                    }

                    // A mapper function in H-Sync
                    MapperHSync();

                    // A function in H-Sync
                    if ( InfoNES_HSync() == -1 )
                      return;  // To the menu screen

                    // HSYNC Wait
                    InfoNES_Wait();

                    static uint16_t n=0;

                    if(n++==1000)
                    {
                        n=0;

                        falg_scankey=1;

                        button_key = ft5206_scan(&mtouch);
                        if(button_key == 5)
                        {
                            goto TEST;
                        }
                        //播放音乐
                        if(button_key == 4)
                            VoicePlayback(2);
                    }

                }
            }

            TEST:

            HAL_RTC_GetTime(&hrtc, &Time, RTC_FORMAT_BCD);
            RTC_DateTypeDef Data;
            HAL_RTC_GetDate(&hrtc, &Data, RTC_FORMAT_BCD);

            //            RTC_Bcd2ToByte(Time.Hours);
            //            printf("时间:%d:%d:%d\r\n",
            //                RTC_Bcd2ToByte(Time.Hours),RTC_Bcd2ToByte(Time.Minutes),RTC_Bcd2ToByte(Time.Seconds));
            //            printf("日期:%d:%d:%d\r\n",
            //                RTC_Bcd2ToByte(Data.Year),RTC_Bcd2ToByte(Data.Month),RTC_Bcd2ToByte(Data.Date));
        }
    }
  /* USER CODE END GUI_MesProcess_Task */
}

void SendContGUIMess_Task(void const * argument)
{
  /* USER CODE BEGIN SendContGUIMess_Task */
    uint16_t t = 0;
    /* Infinite loop */
    for (;;)
    {
        //标记事件组
        xEventGroupSetBits(IWDG_Event, IWDG_Event_3);
        osDelay(10);

        //CPU
        if (osOK == osSemaphoreWait(RenCPUTempBinSemHandle, 0))
        {
            //查看任务情况
            //debugShowOSTasksLists();
            //发送温度更新消息
            osMessagePut(Task_ControlGUIQueueHandle, TaskConGUIQueRenTemp, 0);
        }
        //无线电
        if (osOK == osSemaphoreWait(UpRadioDatBinSemHandle, 0))
        {
            //发送无线电更新消息
            osMessagePut(Task_ControlGUIQueueHandle, TaskConGUIQueUpRadio, 0);
        }

        if (t++ % 50 == 0)
        {
            HAL_GPIO_TogglePin(led_red_GPIO_Port, led_red_Pin);
        }
    }
  /* USER CODE END SendContGUIMess_Task */
}

void StartIwdgTask(void const * argument)
{
  /* USER CODE BEGIN StartIwdgTask */
//    hiwdg1.Instance = IWDG1;
//    hiwdg1.Init.Prescaler = IWDG_PRESCALER_32;
//    hiwdg1.Init.Window = 4000;
//    hiwdg1.Init.Reload = 4000;
//    if (HAL_IWDG_Init(&hiwdg1) != HAL_OK)
//    {
//        Error_Handler();
//    }

    EventBits_t IWDG_EventBits;
    /* Infinite loop */
    for (;;)
    {
        //1.句柄；2.哪些位；3.读完清零；4.全部有效(与逻辑)；5.等待时间
        IWDG_EventBits = xEventGroupWaitBits(IWDG_Event, \
            IWDG_Event_1 | IWDG_Event_2 | IWDG_Event_3 | IWDG_Event_4, \
            pdTRUE, \
            pdTRUE, \
            osWaitForever);

        if ((IWDG_EventBits & (IWDG_Event_1 | IWDG_Event_2 | IWDG_Event_3 | IWDG_Event_4)) \
            == (IWDG_Event_1 | IWDG_Event_2 | IWDG_Event_3 | IWDG_Event_4))
        {
            /* 如果接收完成并且正确 */
            HAL_IWDG_Refresh(&hiwdg1);
        }
        osDelay(10);
    }
  /* USER CODE END StartIwdgTask */
}

/* USER CODE BEGIN Header_PerDataProcess_Task */
/**
* @brief Function implementing the PerDataProcess_ thread.
* @param argument: Not used
* @retval None
*/
uint8_t DateTemp;
/* USER CODE END Header_PerDataProcess_Task */
void PerDataProcess_Task(void const * argument)
{
  /* USER CODE BEGIN PerDataProcess_Task */
    uint16_t t = 0;
    /* Infinite loop */
    for (;;)
    {
        //标记事件组
        xEventGroupSetBits(IWDG_Event, IWDG_Event_4);
        osDelay(10);

        if (osOK == osSemaphoreWait(RadioUART_BinSemHandle, 0))
        {
            //解析无线电状态
            ReadRadioState();
            ParsingUSART();//解析数据

            //校准RTC时间
            RTC_TimeTypeDef sTime = { 0 };
            RTC_DateTypeDef sDate = { 0 };

            RTC_TimeTypeDef Time;
            RTC_DateTypeDef Data;
            HAL_RTC_GetTime(&hrtc, &Time, RTC_FORMAT_BCD);

            HAL_RTC_GetDate(&hrtc, &Data, RTC_FORMAT_BCD);

            if (DateTemp != 0 && RTC_Bcd2ToByte(Data.Year) != 0 && RadioStateStru.State)
            {
                /** Initialize RTC and set the Time and Date
                  */
                sTime.Hours = RTC_ByteToBcd2(Radio_GlobalVariableStruct.GPS_Tim[0]);
                sTime.Minutes = RTC_ByteToBcd2(Radio_GlobalVariableStruct.GPS_Tim[1]);
                sTime.Seconds = RTC_ByteToBcd2(Radio_GlobalVariableStruct.GPS_Tim[2]);
                sTime.DayLightSaving = RTC_DAYLIGHTSAVING_NONE;
                sTime.StoreOperation = RTC_STOREOPERATION_RESET;
                if (HAL_RTC_SetTime(&hrtc, &sTime, RTC_FORMAT_BCD) != HAL_OK)
                {
                    Error_Handler();
                }

                sDate.Month = RTC_ByteToBcd2(Radio_GlobalVariableStruct.GPS_Dat[1]);
                sDate.Date = RTC_ByteToBcd2(Radio_GlobalVariableStruct.GPS_Dat[2]);
                sDate.Year = RTC_ByteToBcd2(Radio_GlobalVariableStruct.GPS_Dat[0]);
                if (HAL_RTC_SetDate(&hrtc, &sDate, RTC_FORMAT_BCD) != HAL_OK)
                {
                    Error_Handler();
                }
            }

            Radio_GlobalVariableStruct.GPS_Tim[0] = RTC_Bcd2ToByte(Time.Hours);
            Radio_GlobalVariableStruct.GPS_Tim[1] = RTC_Bcd2ToByte(Time.Minutes);
            Radio_GlobalVariableStruct.GPS_Tim[2] = RTC_Bcd2ToByte(Time.Seconds);

            RadioRTxStru.DataBuff[34] = RTC_Bcd2ToByte(Data.Year);
            RadioRTxStru.DataBuff[35] = RTC_Bcd2ToByte(Data.Month);
            RadioRTxStru.DataBuff[36] = RTC_Bcd2ToByte(Data.Date);

            osSemaphoreRelease(UpRadioDatBinSemHandle);//释放无线电更新信号量
        }

        if (t++ % 50 == 0)
        {
            //获取CPU温度
            MAIN_FREERTOS_GlobalVariableStruct.CPUtemperature = (uint8_t)GetADC_Temperate();
            osSemaphoreRelease(RenCPUTempBinSemHandle);//释放温度更新信号量
        }
    }
  /* USER CODE END PerDataProcess_Task */
}
